# S32K312_M7 register map
Vendor: NXP Semiconductors; File version: 1.4
CPU: CM7 r0p1, little endian, MPU, FPU, VTOR, 4 interrupt priority bits
Registers are 32-bit, read-write, reset 0x0 unless marked. A register's access mark holds for its fields unless they carry their own. Offsets are from the block's base; [hi:lo] are bit positions; lines under a group give offsets from that group; {n}, {i} and the like mark numbered series.

## PIT_0 — PIT
Base 0x400B0000
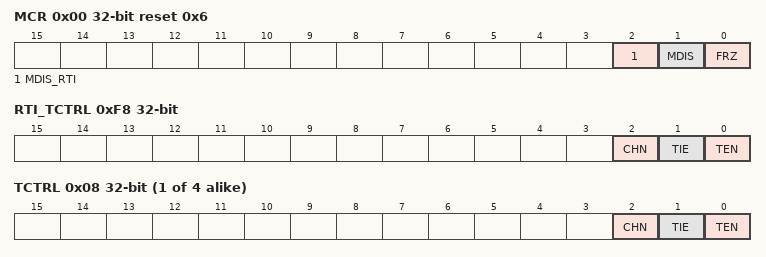
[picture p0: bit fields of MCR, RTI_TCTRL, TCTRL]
0x00 MCR reset 0x6 — PIT Module Control Register
  [2] MDIS_RTI — Module Disable for RTI
    0=t00221 (Clock for RTI timers is enabled); 1=t01881 (Clock for RTI timers is disabled)
  [1] MDIS — Module Disable for PIT
    0=t0301 (Clock for standard PIT timers is enabled.); 1=t00000111 (Clock for standard PIT timers is disabled.)
  [0] FRZ — Freeze
    0=t000001 (Timers continue to run in Debug mode.); 1=t0000011 (Timers are stopped in Debug mode.)
0xE0 LTMR64H ro — PIT Upper Lifetime Timer Register
  [31:0] LTH — Life Timer value
0xE4 LTMR64L ro — PIT Lower Lifetime Timer Register
  [31:0] LTL — Life Timer value
0xEC RTI_LDVAL_STAT write-clears — RTI Timer Load Value Sync Status Register
  [0] RT_STAT write-clears — RTI Timer Load Value Sync Status
    0=t00221112 (RTI_LDVAL register not loaded.); 1=t0022144 (RTI_LDVAL register updated with new value.)
0xF0 RTI_LDVAL — Timer Load Value Register
  [31:0] TSV — Timer Start Value
0xF4 RTI_CVAL ro — Current Timer Value Register
  [31:0] TVL — Current Timer Value
0xF8 RTI_TCTRL — Timer Control Register
  [2] CHN — Chain Mode
  [1] TIE — Timer Interrupt Enable
    0=t0661 (Interrupt requests from the RTI timers are disabled.); 1=t071 (Interrupt is requested whenever TIF is set.)
  [0] TEN — Timer Enable Bit
    0=t0041 (RTI timer is disabled.); 1=t061 (RTI timer is enabled.)
0xFC RTI_TFLG write-1-clears — Timer Flag Register
  [0] TIF write-1-clears — Timer Interrupt Flag
    0=t07321 (Time-out has not yet occurred.); 1=s4071 (Time-out has occurred.)
{0x100+0x10*i} TIMER[{i}] (i=0..3) group — Timer array.
  0x00 LDVAL — Timer Load Value Register
    [31:0] TSV — Timer Start Value
  0x04 CVAL ro — Current Timer Value Register
    [31:0] TVL — Current Timer Value
  0x08 TCTRL — Timer Control Register
    [2] CHN — Chain Mode
      0=timer0001 (Timer is not chained.); 1=timer0081 (Timer is chained to a previous timer. For example, for channel 2, if this field is set, Timer 2 is chained to Timer 1.)
    [1] TIE — Timer Interrupt Enable
      0=t0331 (Interrupt requests from Timer n are disabled.); 1=t077711 (Interrupt is requested whenever TIF is set.)
    [0] TEN — Timer Enable
      0=t02981 (Timer n is disabled.); 1=t008981 (Timer n is enabled.)
  0x0C TFLG write-1-clears — Timer Flag Register
    [0] TIF write-1-clears — Timer Interrupt Flag
      0=t0022331 (Timeout has not yet occurred.); 1=t0022332221 (Timeout has occurred.)

## PIT_1 — PIT
Base 0x400B4000
Registers as PIT_0, without LTMR64H, LTMR64L, RTI_LDVAL_STAT, RTI_LDVAL, RTI_CVAL, RTI_TCTRL, RTI_TFLG; these are added or differ:
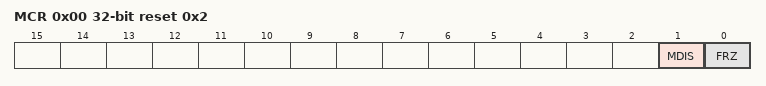
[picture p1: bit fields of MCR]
0x00 MCR reset 0x2 — PIT Module Control Register
  [1] MDIS — Module Disable for PIT
    0=t0301 (Clock for standard PIT timers is enabled.); 1=t00000111 (Clock for standard PIT timers is disabled.)
  [0] FRZ — Freeze
    0=t000001 (Timers continue to run in Debug mode.); 1=t0000011 (Timers are stopped in Debug mode.)

## XBIC_AXBS — XBIC
Base 0x40204000
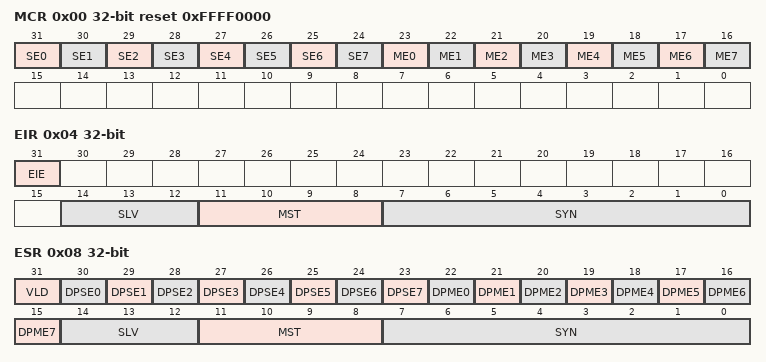
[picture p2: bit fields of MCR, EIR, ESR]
0x00 MCR reset 0xFFFF0000 — XBIC Module Control
  [31-n] SE{n} (n=0..6) — Slave port EDC Error Detection Enable
    0=DISABLED (Attribute integrity checking disabled for slave port {n}); 1=ENABLED (Attribute integrity checking enabled for slave port {n})
  [24] SE7 — Slave Port EDC Error Detection Enable
    0=DISABLED (Attribute integrity checking disabled for slave port 7); 1=ENABLED (Attribute integrity checking enabled for slave port 7)
  [23-n] ME{n} (n=0..7) — Master Port Enable For Feedback Integrity Check
    0=DISABLED (Feedback integrity checking disabled for master port {n}); 1=ENABLED (Feedback integrity checking enabled for master port {n})
0x04 EIR — XBIC Error Injection
  [31] EIE — Error Injection Enable
    0=DISABLED (Error injection disabled); 1=ENABLED (Error injection enabled)
  [14:12] SLV — Target Slave Port
  [11:8] MST — Target Master ID
  [7:0] SYN — Syndrome
0x08 ESR ro — XBIC Error Status
  [31] VLD — Error Status Valid
    0=NO_ERROR (No error detected-other fields of the ESR and EAR registers are invalid); 1=ERROR (Error detected-all fields of the ESR and EAR registers are valid)
  [30-n] DPSE{n} (n=0..7) — Data Phase Slave Port Error
    0=NO_ERROR (No feedback integrity error detected on slave port {n}); 1=ERROR (Feedback integrity error detected on slave port {n})
  [22-n] DPME{n} (n=0..7) — Data Phase Master Port Error
    0=NO_ERROR (No feedback integrity error detected on master port {n}); 1=ERROR (Feedback integrity error detected on master port {n})
  [14:12] SLV — Slave Port
  [11:8] MST — Master ID
  [7:0] SYN — Syndrome
0x0C EAR ro — XBIC Error Address
  [31:0] ADDR — Error Address
